AUTOSAR XML (schema 00044)
package /ComponentTypes
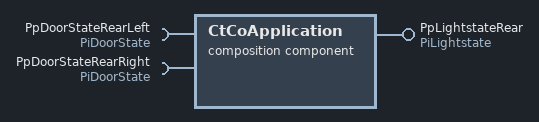
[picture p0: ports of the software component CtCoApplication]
  composition sw component type CtCoApplication
    provide port PpLightstateRear: nonqueued-sender-com-spec{data-element=DeLightstate, init-value=0}, provided-interface=PiLightstate
    require port PpDoorStateRearLeft: nonqueued-receiver-com-spec{data-element=DeDoorState, init-value=0}, required-interface=PiDoorState
    require port PpDoorStateRearRight: nonqueued-receiver-com-spec{data-element=DeDoorState, init-value=0}, required-interface=PiDoorState
    5 x component:
      CpApMySwc: type=CtApMySwc
      CpSaDoorFrontLeft: type=CtSaDoor
      CpSalnteriorLight: type=CtSalnteriorLight
      CpSaDoorFrontRight: type=CtSaDoor
      CtCddloHwAb: type=CtCddloHwAb
    connect CpApMySwc.PpLightStateFront -> CpSalnteriorLight.PpLightstate
    connect CpSaDoorFrontLeft.PpDoorState -> CpApMySwc.PpDoorStateFrontLeft
    connect CpSaDoorFrontRight.PpDoorState -> CpApMySwc.PpDoorStateFrontRight
    connect CtCddloHwAb.PpInteriorLightFront -> CpSalnteriorLight.PpInteriorLightloHwAb
    connect CtCddloHwAb.PpDoorFrontLeft -> CpSaDoorFrontLeft.PpDoorloHwAb
    connect CtCddloHwAb.PpDoorFrontRight -> CpSaDoorFrontRight.PpDoorloHwAb
    delegate CpApMySwc.PpLightstateRear <-> outer port PpLightstateRear
    delegate CpApMySwc.PpDoorStateRearLeft <-> outer port PpDoorStateRearLeft
    delegate CpApMySwc.PpDoorStateRearRight <-> outer port PpDoorStateRearRight
